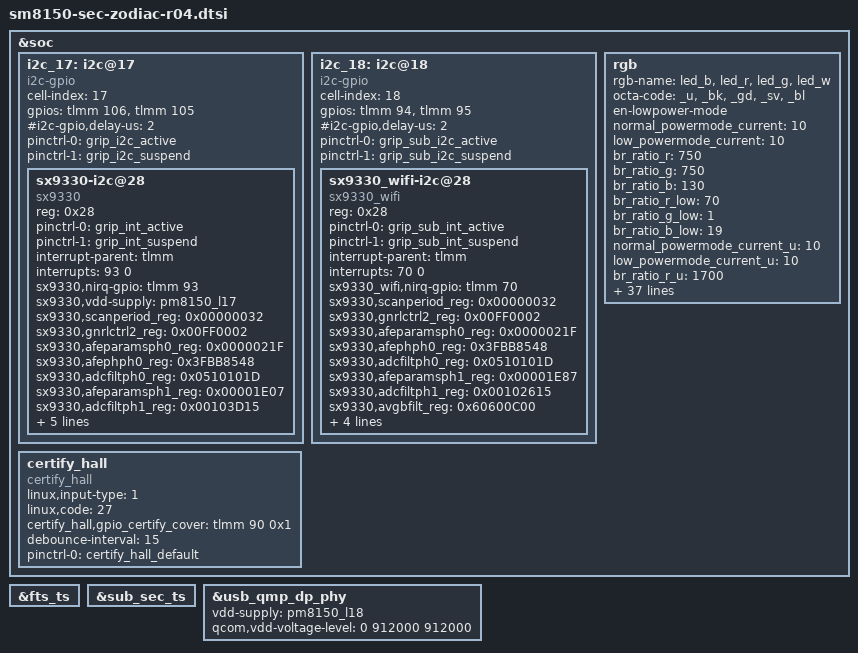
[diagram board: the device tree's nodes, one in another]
/* Copyright (c) 2016-2017, The Linux Foundation. All rights reserved.
 *
 * This program is free software; you can redistribute it and/or modify
 * it under the terms of the GNU General Public License version 2 and
 * only version 2 as published by the Free Software Foundation.
 *
 * This program is distributed in the hope that it will be useful,
 * but WITHOUT ANY WARRANTY; without even the implied warranty of
 * MERCHANTABILITY or FITNESS FOR A PARTICULAR PURPOSE.  See the
 * GNU General Public License for more details.
 */

#include "sm8150-sec-zodiac-common.dtsi"
#include "sm8150-sec-zodiac-optics-r00.dtsi"

&soc {
	i2c_17: i2c@17 { /* SW I2C */
		status = "ok";

		cell-index = <17>;
		compatible = "i2c-gpio";
		gpios = <&tlmm 106 0 /* sda */
			 &tlmm 105 0 /* scl */
		>;
		#i2c-gpio,delay-us = <2>;
		#address-cells = <1>;
		#size-cells = <0>;

		pinctrl-names = "default", "sleep";
		pinctrl-0 = <&grip_i2c_active>;
		pinctrl-1 = <&grip_i2c_suspend>;

		sx9330-i2c@28 {
			compatible = "sx9330";
			reg = <0x28>;

			pinctrl-names = "default", "sleep";
			pinctrl-0 = <&grip_int_active>;
			pinctrl-1 = <&grip_int_suspend>;

			interrupt-parent = <&tlmm>;
			interrupts = <93 0>;

			sx9330,nirq-gpio = <&tlmm 93 0>;
			sx9330,vdd-supply = <&pm8150_l17>;

			sx9330,scanperiod_reg = <0x00000032>; /* scanperiod : 102ms */
			sx9330,gnrlctrl2_reg = <0x00FF0002>;
			sx9330,afeparamsph0_reg = <0x0000021F>;
			sx9330,afephph0_reg = <0x3FBB8548>;
			sx9330,adcfiltph0_reg = <0x0510101D>;
			sx9330,afeparamsph1_reg = <0x00001E07>;  /* again : 9.9pF, sampling freq : 250khz */
			sx9330,adcfiltph1_reg = <0x00103D15>;    /* threshold : 1860 */
			sx9330,avgbfilt_reg = <0x60600C00>;   /* AVGPOSFILT : 1/256, AVGNEGFILT : 1/2 */
			sx9330,avgafilt_reg = <0x00000000>;
			sx9330,advdig3_reg = <0x00000000>;
			sx9330,advdig4_reg = <0x00000000>;
			sx9330,refcorra_reg = <0x00000000>;
		};
	};

	i2c_18: i2c@18 { /* SW I2C */
		status = "ok";

		cell-index = <18>;
		compatible = "i2c-gpio";
		gpios = <&tlmm 94 0 /* sda */
			 &tlmm 95 0 /* scl */
		>;
		#i2c-gpio,delay-us = <2>;
		#address-cells = <1>;
		#size-cells = <0>;

		pinctrl-names = "default", "sleep";
		pinctrl-0 = <&grip_sub_i2c_active>;
		pinctrl-1 = <&grip_sub_i2c_suspend>;

		sx9330_wifi-i2c@28 {
			compatible = "sx9330_wifi";
			reg = <0x28>;

			pinctrl-names = "default", "sleep";
			pinctrl-0 = <&grip_sub_int_active>;
			pinctrl-1 = <&grip_sub_int_suspend>;

			interrupt-parent = <&tlmm>;
			interrupts = <70 0>;

			sx9330_wifi,nirq-gpio = <&tlmm 70 0>;

			sx9330,scanperiod_reg = <0x00000032>; /* scanperiod : 102ms */
			sx9330,gnrlctrl2_reg = <0x00FF0002>;
			sx9330,afeparamsph0_reg = <0x0000021F>;
			sx9330,afephph0_reg = <0x3FBB8548>;
			sx9330,adcfiltph0_reg = <0x0510101D>;
			sx9330,afeparamsph1_reg = <0x00001E87>;  /* again : 9.9pF, sampling freq : 50khz */
			sx9330,adcfiltph1_reg = <0x00102615>;    /* threshold : 722 */
			sx9330,avgbfilt_reg = <0x60600C00>;   /* AVGPOSFILT : 1/256, AVGNEGFILT : 1/2 */
			sx9330,avgafilt_reg = <0x00000000>;
			sx9330,advdig3_reg = <0x00000000>;
			sx9330,advdig4_reg = <0x00000000>;
			sx9330,refcorra_reg = <0x00000000>;			
		};
	};

        certify_hall {
                compatible = "certify_hall";
                linux,input-type = <1>;
                linux,code = <27>;
                certify_hall,gpio_certify_cover = <&tlmm 90 0x1>;
                debounce-interval = <15>;
		pinctrl-names = "default";
	        pinctrl-0 = <&certify_hall_default>;
        };

	rgb {
		device_type = "star1";
		rgb-name = "led_b", "led_r", "led_g", "led_w";
		octa-code = "_u", "_bk", "_gd", "_sv", "_bl";

		en-lowpower-mode;

		normal_powermode_current = <10>;
		low_powermode_current = <10>;
		br_ratio_r = <750>;
		br_ratio_g = <750>;
		br_ratio_b = <130>;
		br_ratio_r_low = <70>;
		br_ratio_g_low = <1>;
		br_ratio_b_low = <19>;

		normal_powermode_current_u = <10>;
		low_powermode_current_u = <10>;
		br_ratio_r_u = <1700>;
		br_ratio_g_u = <1300>;
		br_ratio_b_u = <130>;
		br_ratio_r_low_u = <70>;
		br_ratio_g_low_u = <1>;
		br_ratio_b_low_u = <19>;

		normal_powermode_current_bk = <10>;
		low_powermode_current_bk = <10>;
		br_ratio_r_bk = <750>;
		br_ratio_g_bk = <70>;
		br_ratio_b_bk = <130>;
		br_ratio_r_low_bk = <70>;
		br_ratio_g_low_bk = <1>;
		br_ratio_b_low_bk = <19>;

		normal_powermode_current_gd = <10>;
		low_powermode_current_gd = <10>;
		br_ratio_r_gd = <750>;
		br_ratio_g_gd = <70>;
		br_ratio_b_gd = <130>;
		br_ratio_r_low_gd = <70>;
		br_ratio_g_low_gd = <1>;
		br_ratio_b_low_gd = <19>;

		normal_powermode_current_sv = <10>;
		low_powermode_current_sv = <10>;
		br_ratio_r_sv = <750>;
		br_ratio_g_sv = <70>;
		br_ratio_b_sv = <130>;
		br_ratio_r_low_sv = <70>;
		br_ratio_g_low_sv = <1>;
		br_ratio_b_low_sv = <19>;

		normal_powermode_current_bl = <10>;
		low_powermode_current_bl = <10>;
		br_ratio_r_bl = <750>;
		br_ratio_g_bl = <70>;
		br_ratio_b_bl = <130>;
		br_ratio_r_low_bl = <70>;
		br_ratio_g_low_bl = <1>;
		br_ratio_b_low_bl = <19>;
	};

};

&fts_ts { /* main_tsp */
	status = "ok";
};

&sub_sec_ts { /* sub_tsp */
	status = "ok";
};

&usb_qmp_dp_phy {
	vdd-supply = <&pm8150_l18>;
	qcom,vdd-voltage-level = <0 912000 912000>;
};
